# STM32U575 register map
File version: 1.4
CPU: CM33 r0p1, little endian, MPU, FPU, 4 interrupt priority bits
Registers are 32-bit, read-write, reset 0x0 unless marked. A register's access mark holds for its fields unless they carry their own. Offsets are from the block's base; [hi:lo] are bit positions; {n}, {i} and the like mark numbered series.

## WWDG — System window watchdog
Base 0x40002C00
Same registers: SEC_WWDG 0x50002C00
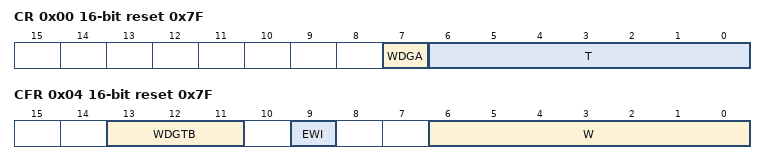
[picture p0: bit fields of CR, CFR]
0x00 CR 16-bit reset 0x7F — Control register
  [7] WDGA — Activation bit
    0=Disabled (Watchdog disabled); 1=Enabled (Watchdog enabled)
  [6:0] T — 7-bit counter (MSB to LSB)
0x04 CFR 16-bit reset 0x7F — Configuration register
  [13:11] WDGTB — Timer base
    0=Div1 (Counter clock (PCLK1 div 4096) div 1); 1=Div2 (Counter clock (PCLK1 div 4096) div 2); 2=Div4 (Counter clock (PCLK1 div 4096) div 4); 3=Div8 (Counter clock (PCLK1 div 4096) div 8); 4=Div16 (Counter clock (PCLK1 div 4096) div 16); 5=Div32 (Counter clock (PCLK1 div 4096) div 32); 6=Div64 (Counter clock (PCLK1 div 4096) div 64); 7=Div128 (Counter clock (PCLK1 div 4096) div 128)
  [9] EWI — Early wakeup interrupt
    on write: 1=Enable (interrupt occurs whenever the counter reaches the value 0x40)
  [6:0] W — 7-bit window value
0x08 SR 16-bit — Status register
  [0] EWIF write-0-clears — Early wakeup interrupt flag
    on read: 0=Finished (The EWI Interrupt Service Routine has been serviced); 1=Pending (The EWI Interrupt Service Routine has been triggered) | on write: 0=Finished (The EWI Interrupt Service Routine has been serviced)

## SYSCFG — System configuration controller
Base 0x46000400
Same registers: SEC_SYSCFG 0x56000400
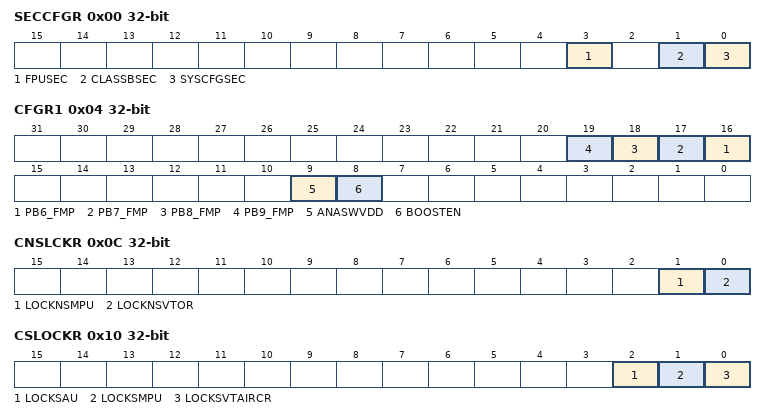
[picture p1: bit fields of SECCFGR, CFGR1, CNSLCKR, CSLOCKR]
0x00 SECCFGR — SYSCFG secure configuration register
  [3] FPUSEC
  [1] CLASSBSEC
  [0] SYSCFGSEC — SYSCFG clock control security
0x04 CFGR1 — configuration register 1
  [n+10] PB{n}_FMP (n=6..9)
  [9] ANASWVDD — GPIO analog switch control voltage selection
  [8] BOOSTEN — I/O analog switch voltage booster enable
0x08 FPUIMR reset 0x1F — FPU interrupt mask register
  [5:0] FPU_IE — Floating point unit interrupts enable bits
0x0C CNSLCKR — SYSCFG CPU non-secure lock register
  [1] LOCKNSMPU — Non-secure MPU registers lock
  [0] LOCKNSVTOR — VTOR_NS register lock
0x10 CSLOCKR — SYSCFG CPU secure lock register
  [2] LOCKSAU, [1] LOCKSMPU, [0] LOCKSVTAIRCR
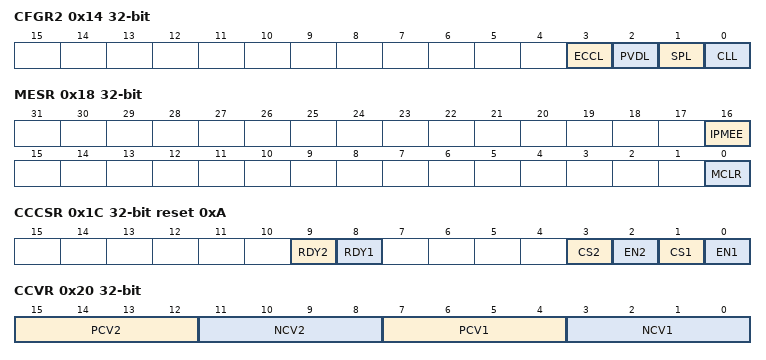
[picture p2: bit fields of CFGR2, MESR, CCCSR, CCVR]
0x14 CFGR2 — configuration register 2
  [3] ECCL — ECC Lock
  [2] PVDL — PVD lock enable bit
  [1] SPL — SRAM ECC lock bit
  [0] CLL — LOCKUP (hardfault) output enable bit
0x18 MESR — memory erase status register
  [16] IPMEE, [0] MCLR
0x1C CCCSR access per field reset 0xA — compensation cell control/status register
  [9] RDY2 ro, [8] RDY1 ro, [3] CS2 rw, [2] EN2 rw, [1] CS1 rw, [0] EN1 rw
0x20 CCVR ro — compensation cell value register
  [15:12] PCV2, [11:8] NCV2, [7:4] PCV1, [3:0] NCV1
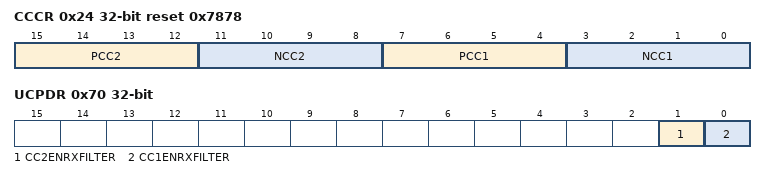
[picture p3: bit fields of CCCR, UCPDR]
0x24 CCCR reset 0x7878 — compensation cell code register
  [15:12] PCC2, [11:8] NCC2, [7:4] PCC1, [3:0] NCC1
0x2C RSSCMDR — RSS command register
  [15:0] RSSCMD — RSS commands
0x70 UCPDR — USB Type C and Power Delivery register
  [1] CC2ENRXFILTER, [0] CC1ENRXFILTER

## PKA — Private key accelerator
Base 0x420C2000
Same registers: SEC_PKA 0x520C2000
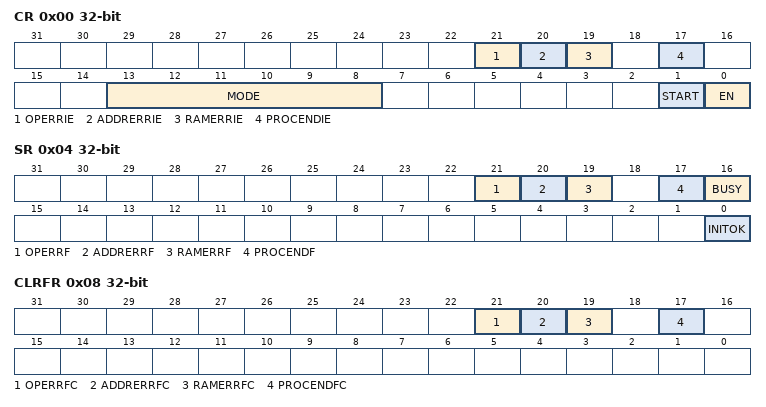
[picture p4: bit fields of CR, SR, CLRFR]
0x00 CR — Control register
  [21] OPERRIE — Operation error interrupt enable
  [20] ADDRERRIE — Address error interrupt enable
  [19] RAMERRIE — RAM error interrupt enable
  [17] PROCENDIE — End of operation interrupt enable
  [13:8] MODE — PKA Operation Mode
  [1] START — Start the operation
  [0] EN — Peripheral Enable
0x04 SR ro — PKA status register
  [21] OPERRF
  [20] ADDRERRF
  [19] RAMERRF
  [17] PROCENDF — PKA End of Operation flag
  [16] BUSY — PKA operation is in progress
  [0] INITOK
0x08 CLRFR wo — PKA clear flag register
  [21] OPERRFC
  [20] ADDRERRFC
  [19] RAMERRFC
  [17] PROCENDFC — Clear PKA End of Operation flag

## LPUART1 — Universal synchronous asynchronous receiver transmitter
Base 0x46002400
Same registers: SEC_LPUART1 0x56002400
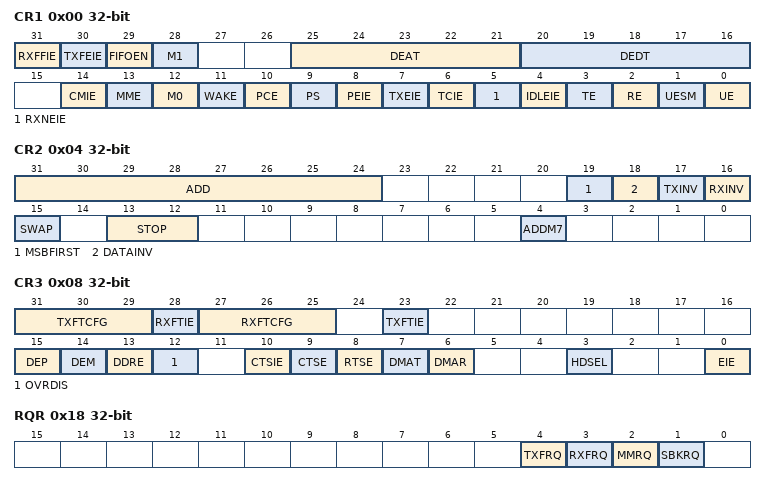
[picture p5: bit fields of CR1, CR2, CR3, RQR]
0x00 CR1 — Control register 1
  [31] RXFFIE
  [30] TXFEIE
  [29] FIFOEN
  [28] M1 — Word length
  [25:21] DEAT
  [20:16] DEDT
  [14] CMIE — Character match interrupt enable
  [13] MME — Mute mode enable
  [12] M0 — Word length
  [11] WAKE — Receiver wakeup method
  [10] PCE — Parity control enable
  [9] PS — Parity selection
  [8] PEIE — PE interrupt enable
  [7] TXEIE — TXFIFO not full interrupt enable
  [6] TCIE — Transmission complete interrupt enable
  [5] RXNEIE — RXFNEIE
  [4] IDLEIE — IDLE interrupt enable
  [3] TE — Transmitter enable
  [2] RE — Receiver enable
  [1] UESM — USART enable in Stop mode
  [0] UE — USART enable
0x04 CR2 — Control register 2
  [31:24] ADD — Address of the LPUART node
  [19] MSBFIRST — Most significant bit first
  [18] DATAINV — Binary data inversion
  [17] TXINV — TX pin active level inversion
  [16] RXINV — RX pin active level inversion
  [15] SWAP — Swap TX/RX pins
  [13:12] STOP — STOP bits
  [4] ADDM7 — 7-bit Address Detection/4-bit Address Detection
0x08 CR3 — Control register 3
  [31:29] TXFTCFG
  [28] RXFTIE
  [27:25] RXFTCFG
  [23] TXFTIE
  [15] DEP — Driver enable polarity selection
  [14] DEM — Driver enable mode
  [13] DDRE — DMA Disable on Reception Error
  [12] OVRDIS — Overrun Disable
  [10] CTSIE — CTS interrupt enable
  [9] CTSE — CTS enable
  [8] RTSE — RTS enable
  [7] DMAT — DMA enable transmitter
  [6] DMAR — DMA enable receiver
  [3] HDSEL — Half-duplex selection
  [0] EIE — Error interrupt enable
0x0C BRR — Baud rate register
  [19:0] BRR
0x18 RQR wo — Request register
  [4] TXFRQ
  [3] RXFRQ — Receive data flush request
  [2] MMRQ — Mute mode request
  [1] SBKRQ — Send break request
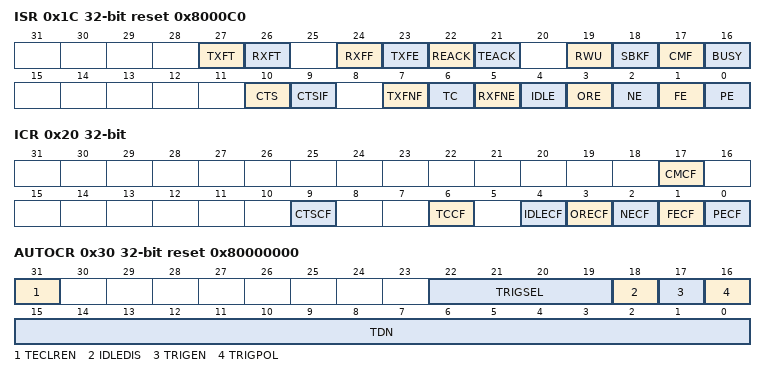
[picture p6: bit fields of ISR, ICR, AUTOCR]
0x1C ISR ro reset 0x8000C0 — Interrupt and status register
  [27] TXFT, [26] RXFT, [24] RXFF, [23] TXFE, [22] REACK, [21] TEACK, [19] RWU, [18] SBKF, [17] CMF, [16] BUSY, [10] CTS, [9] CTSIF, [7] TXFNF, [6] TC, [5] RXFNE, [4] IDLE, [3] ORE, [2] NE, [1] FE, [0] PE
0x20 ICR wo — Interrupt flag clear register
  [17] CMCF — Character match clear flag
  [9] CTSCF — CTS clear flag
  [6] TCCF — Transmission complete clear flag
  [4] IDLECF — Idle line detected clear flag
  [3] ORECF — Overrun error clear flag
  [2] NECF — Noise detected clear flag
  [1] FECF — Framing error clear flag
  [0] PECF — Parity error clear flag
0x24 RDR ro — Receive data register
  [8:0] RDR — Receive data value
0x28 TDR — Transmit data register
  [8:0] TDR — Transmit data value
0x2C PRESC — prescaler register
  [3:0] PRESCALER
0x30 AUTOCR reset 0x80000000 — Autonomous mode control register
  [31] TECLREN, [22:19] TRIGSEL, [18] IDLEDIS, [17] TRIGEN, [16] TRIGPOL, [15:0] TDN
